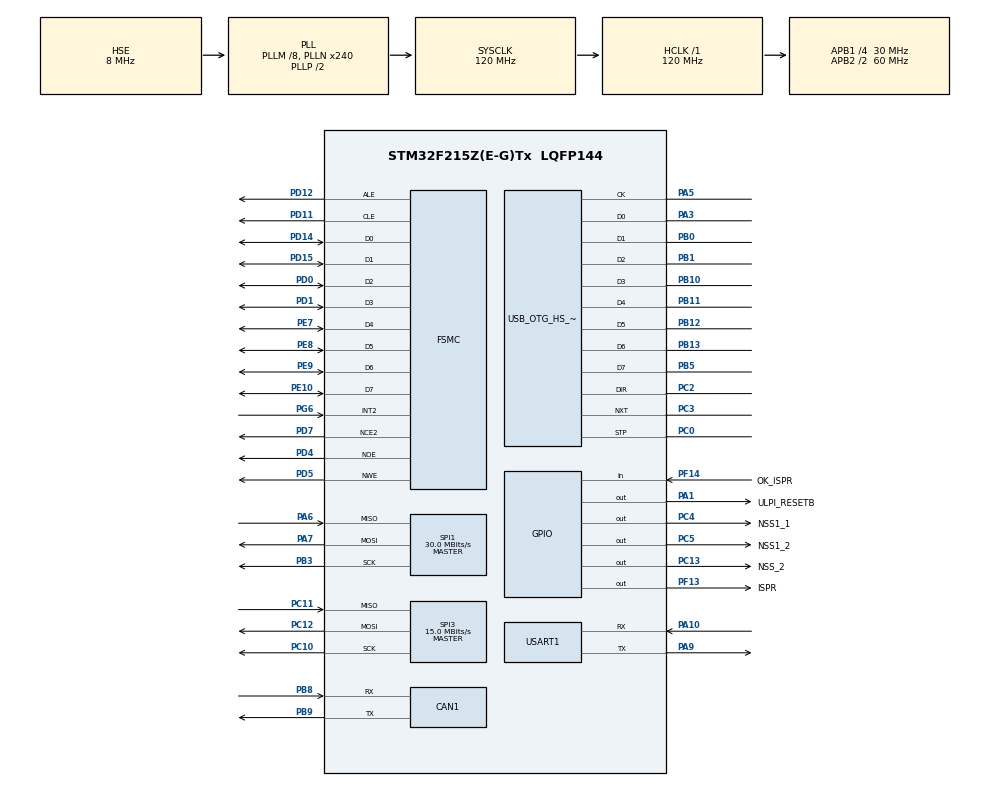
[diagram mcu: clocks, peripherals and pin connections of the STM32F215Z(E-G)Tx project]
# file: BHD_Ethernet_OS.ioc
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CAN1.BS1=CAN_BS1_1TQ
CAN1.BS2=CAN_BS2_1TQ
CAN1.CalculateTimeQuantum=533.3333333333334
Dma.Request0=USART1_RX
Dma.Request1=USART1_TX
Dma.Request2=SPI1_RX
Dma.Request3=SPI1_TX
Dma.Request4=SPI3_RX
Dma.Request5=SPI3_TX
Dma.SPI1_RX.2.Direction=DMA_PERIPH_TO_MEMORY
Dma.SPI1_RX.2.FIFOMode=DMA_FIFOMODE_DISABLE
Dma.SPI1_RX.2.Instance=DMA2_Stream0
Dma.SPI1_RX.2.MemDataAlignment=DMA_MDATAALIGN_BYTE
Dma.SPI1_RX.2.MemInc=DMA_MINC_ENABLE
Dma.SPI1_RX.2.Mode=DMA_NORMAL
Dma.SPI1_RX.2.PeriphDataAlignment=DMA_PDATAALIGN_BYTE
Dma.SPI1_RX.2.PeriphInc=DMA_PINC_DISABLE
Dma.SPI1_RX.2.Priority=DMA_PRIORITY_LOW
Dma.SPI1_TX.3.Direction=DMA_MEMORY_TO_PERIPH
Dma.SPI1_TX.3.FIFOMode=DMA_FIFOMODE_DISABLE
Dma.SPI1_TX.3.Instance=DMA2_Stream3
Dma.SPI1_TX.3.MemDataAlignment=DMA_MDATAALIGN_BYTE
Dma.SPI1_TX.3.MemInc=DMA_MINC_ENABLE
Dma.SPI1_TX.3.Mode=DMA_NORMAL
Dma.SPI1_TX.3.PeriphDataAlignment=DMA_PDATAALIGN_BYTE
Dma.SPI1_TX.3.PeriphInc=DMA_PINC_DISABLE
Dma.SPI1_TX.3.Priority=DMA_PRIORITY_LOW
Dma.SPI3_RX.4.Direction=DMA_PERIPH_TO_MEMORY
Dma.SPI3_RX.4.FIFOMode=DMA_FIFOMODE_DISABLE
Dma.SPI3_RX.4.Instance=DMA1_Stream0
Dma.SPI3_RX.4.MemDataAlignment=DMA_MDATAALIGN_BYTE
Dma.SPI3_RX.4.MemInc=DMA_MINC_ENABLE
Dma.SPI3_RX.4.Mode=DMA_NORMAL
Dma.SPI3_RX.4.PeriphDataAlignment=DMA_PDATAALIGN_BYTE
Dma.SPI3_RX.4.PeriphInc=DMA_PINC_DISABLE
Dma.SPI3_RX.4.Priority=DMA_PRIORITY_LOW
Dma.SPI3_TX.5.Direction=DMA_MEMORY_TO_PERIPH
Dma.SPI3_TX.5.FIFOMode=DMA_FIFOMODE_DISABLE
Dma.SPI3_TX.5.Instance=DMA1_Stream5
Dma.SPI3_TX.5.MemDataAlignment=DMA_MDATAALIGN_BYTE
Dma.SPI3_TX.5.MemInc=DMA_MINC_ENABLE
Dma.SPI3_TX.5.Mode=DMA_NORMAL
Dma.SPI3_TX.5.PeriphDataAlignment=DMA_PDATAALIGN_BYTE
Dma.SPI3_TX.5.PeriphInc=DMA_PINC_DISABLE
Dma.SPI3_TX.5.Priority=DMA_PRIORITY_LOW
Dma.USART1_RX.0.Direction=DMA_PERIPH_TO_MEMORY
Dma.USART1_RX.0.FIFOMode=DMA_FIFOMODE_DISABLE
Dma.USART1_RX.0.Instance=DMA2_Stream2
Dma.USART1_RX.0.MemDataAlignment=DMA_MDATAALIGN_BYTE
Dma.USART1_RX.0.MemInc=DMA_MINC_ENABLE
Dma.USART1_RX.0.Mode=DMA_NORMAL
Dma.USART1_RX.0.PeriphDataAlignment=DMA_PDATAALIGN_BYTE
Dma.USART1_RX.0.PeriphInc=DMA_PINC_DISABLE
Dma.USART1_RX.0.Priority=DMA_PRIORITY_LOW
Dma.USART1_TX.1.Direction=DMA_MEMORY_TO_PERIPH
Dma.USART1_TX.1.FIFOMode=DMA_FIFOMODE_DISABLE
Dma.USART1_TX.1.Instance=DMA2_Stream7
Dma.USART1_TX.1.MemDataAlignment=DMA_MDATAALIGN_BYTE
Dma.USART1_TX.1.MemInc=DMA_MINC_ENABLE
Dma.USART1_TX.1.Mode=DMA_NORMAL
Dma.USART1_TX.1.PeriphDataAlignment=DMA_PDATAALIGN_BYTE
Dma.USART1_TX.1.PeriphInc=DMA_PINC_DISABLE
Dma.USART1_TX.1.Priority=DMA_PRIORITY_LOW
FREERTOS.Tasks01=defaultTask,24,128,StartDefaultTask,Default,NULL,Dynamic,NULL,NULL
FREERTOS.configCHECK_FOR_STACK_OVERFLOW=2
FREERTOS.configUSE_MALLOC_FAILED_HOOK=1
FREERTOS.configUSE_TICK_HOOK=1
Mcu.Family=STM32F2
Mcu.Name=STM32F215Z(E-G)Tx
Mcu.Package=LQFP144
NVIC.DMA1_Stream0_IRQn=true\:5\:0\:false\:false\:true\:true\:false\:true
NVIC.DMA1_Stream5_IRQn=true\:5\:0\:false\:false\:true\:true\:false\:true
NVIC.DMA2_Stream0_IRQn=true\:5\:0\:false\:false\:true\:true\:false\:true
NVIC.DMA2_Stream2_IRQn=true\:5\:0\:false\:false\:true\:true\:false\:true
NVIC.DMA2_Stream3_IRQn=true\:5\:0\:false\:false\:true\:true\:false\:true
NVIC.DMA2_Stream7_IRQn=true\:5\:0\:false\:false\:true\:true\:false\:true
NVIC.OTG_HS_IRQn=true\:5\:0\:false\:false\:true\:true\:false\:true
NVIC.PriorityGroup=NVIC_PRIORITYGROUP_4
NVIC.TIM1_UP_TIM10_IRQn=true\:0\:0\:false\:false\:true\:false\:false\:true
NVIC.TimeBase=TIM1_UP_TIM10_IRQn
NVIC.TimeBaseIP=TIM10
PA1.GPIO_Label=ULPI_RESETB
PA1.Signal=GPIO_Output
PA10.Mode=Asynchronous
PA10.Signal=USART1_RX
PA13.Mode=Serial_Wire
PA13.Signal=SYS_JTMS-SWDIO
PA14.Mode=Serial_Wire
PA14.Signal=SYS_JTCK-SWCLK
PA3.Mode=Device_HS
PA3.Signal=USB_OTG_HS_ULPI_D0
PA5.Mode=Device_HS
PA5.Signal=USB_OTG_HS_ULPI_CK
PA6.Mode=Full_Duplex_Master
PA6.Signal=SPI1_MISO
PA7.Mode=Full_Duplex_Master
PA7.Signal=SPI1_MOSI
PA9.Mode=Asynchronous
PA9.Signal=USART1_TX
PB0.Mode=Device_HS
PB0.Signal=USB_OTG_HS_ULPI_D1
PB1.Mode=Device_HS
PB1.Signal=USB_OTG_HS_ULPI_D2
PB10.Mode=Device_HS
PB10.Signal=USB_OTG_HS_ULPI_D3
PB11.Mode=Device_HS
PB11.Signal=USB_OTG_HS_ULPI_D4
PB12.Mode=Device_HS
PB12.Signal=USB_OTG_HS_ULPI_D5
PB13.Mode=Device_HS
PB13.Signal=USB_OTG_HS_ULPI_D6
PB3.Mode=Full_Duplex_Master
PB3.Signal=SPI1_SCK
PB5.Mode=Device_HS
PB5.Signal=USB_OTG_HS_ULPI_D7
PB8.Mode=Master
PB8.Signal=CAN1_RX
PB9.Mode=Master
PB9.Signal=CAN1_TX
PC0.Mode=Device_HS
PC0.Signal=USB_OTG_HS_ULPI_STP
PC10.Mode=Full_Duplex_Master
PC10.Signal=SPI3_SCK
PC11.Mode=Full_Duplex_Master
PC11.Signal=SPI3_MISO
PC12.Mode=Full_Duplex_Master
PC12.Signal=SPI3_MOSI
PC13.GPIO_Label=NSS_2
PC13.Signal=GPIO_Output
PC2.Mode=Device_HS
PC2.Signal=USB_OTG_HS_ULPI_DIR
PC3.Mode=Device_HS
PC3.Signal=USB_OTG_HS_ULPI_NXT
PC4.GPIO_Label=NSS1_1
PC4.Signal=GPIO_Output
PC5.GPIO_Label=NSS1_2
PC5.Signal=GPIO_Output
PD0.Signal=FSMC_D2_DA2
PD1.Signal=FSMC_D3_DA3
PD11.Signal=FSMC_A16_CLE
PD12.Signal=FSMC_A17_ALE
PD14.Signal=FSMC_D0_DA0
PD15.Signal=FSMC_D1_DA1
PD4.Signal=FSMC_NOE
PD5.Signal=FSMC_NWE
PD7.Mode=NandChipSelect2_1
PD7.Signal=FSMC_NCE2
PE10.Signal=FSMC_D7_DA7
PE7.Signal=FSMC_D4_DA4
PE8.Signal=FSMC_D5_DA5
PE9.Signal=FSMC_D6_DA6
PF13.GPIO_Label=ISPR
PF13.Signal=GPIO_Output
PF14.GPIO_Label=OK_ISPR
PF14.Signal=GPIO_Input
PG6.Signal=FSMC_INT2
PH0-OSC_IN.Mode=HSE-External-Oscillator
PH0-OSC_IN.Signal=RCC_OSC_IN
PH1-OSC_OUT.Mode=HSE-External-Oscillator
PH1-OSC_OUT.Signal=RCC_OSC_OUT
ProjectManager.HeapSize=0x200
ProjectManager.StackSize=0x400
ProjectManager.TargetToolchain=MDK-ARM V5.27
RCC.48MHZClocksFreq_Value=60000000
RCC.AHBFreq_Value=120000000
RCC.APB1CLKDivider=RCC_HCLK_DIV4
RCC.APB1Freq_Value=30000000
RCC.APB1TimFreq_Value=60000000
RCC.APB2CLKDivider=RCC_HCLK_DIV2
RCC.APB2Freq_Value=60000000
RCC.APB2TimFreq_Value=120000000
RCC.CortexFreq_Value=120000000
RCC.EnbaleCSS=true
RCC.HCLKFreq_Value=120000000
RCC.HSE_VALUE=8000000
RCC.HSI_VALUE=16000000
RCC.LSE_VALUE=32768
RCC.PLLM=8
RCC.PLLN=240
RCC.PLLSourceVirtual=RCC_PLLSOURCE_HSE
RCC.SYSCLKFreq_VALUE=120000000
RCC.SYSCLKSource=RCC_SYSCLKSOURCE_PLLCLK
RCC.VCOOutputFreq_Value=240000000
SH.FSMC_A16_CLE.0=FSMC_CLE,8b-dmux1
SH.FSMC_A17_ALE.0=FSMC_ALE,8b-dmux1
SH.FSMC_D0_DA0.0=FSMC_D0,8b-dmux1
SH.FSMC_D1_DA1.0=FSMC_D1,8b-dmux1
SH.FSMC_D2_DA2.0=FSMC_D2,8b-dmux1
SH.FSMC_D3_DA3.0=FSMC_D3,8b-dmux1
SH.FSMC_D4_DA4.0=FSMC_D4,8b-dmux1
SH.FSMC_D5_DA5.0=FSMC_D5,8b-dmux1
SH.FSMC_D6_DA6.0=FSMC_D6,8b-dmux1
SH.FSMC_D7_DA7.0=FSMC_D7,8b-dmux1
SH.FSMC_INT2.0=FSMC_INT2,Interrupt21
SH.FSMC_NOE.0=FSMC_NOE,8b-dmux1
SH.FSMC_NWE.0=FSMC_NWE,8b-dmux1
SPI1.BaudRatePrescaler=SPI_BAUDRATEPRESCALER_2
SPI1.CalculateBaudRate=30.0 MBits/s
SPI1.Direction=SPI_DIRECTION_2LINES
SPI1.Mode=SPI_MODE_MASTER
SPI1.VirtualType=VM_MASTER
SPI3.BaudRatePrescaler=SPI_BAUDRATEPRESCALER_2
SPI3.CalculateBaudRate=15.0 MBits/s
SPI3.Direction=SPI_DIRECTION_2LINES
SPI3.Mode=SPI_MODE_MASTER
SPI3.VirtualType=VM_MASTER
USART1.VirtualMode=VM_ASYNC
USB_DEVICE.CLASS_NAME_HS=CDC
USB_DEVICE.VirtualMode-CDC_HS=Cdc
USB_DEVICE.VirtualModeHS=Cdc_HS
USB_OTG_HS.VirtualMode-Device_HS=Device_HS
VP_FREERTOS_VS_CMSIS_V2.Mode=CMSIS_V2
VP_SYS_VS_tim10.Mode=TIM10
VP_USB_DEVICE_VS_USB_DEVICE_CDC_HS.Mode=CDC_HS
board=custom

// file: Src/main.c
/* USER CODE BEGIN Header */
/**
  ******************************************************************************
  * @file           : main.c
  * @brief          : Main program body
  ******************************************************************************
  * @attention
  *
  * <h2><center>&copy; Copyright (c) 2019 STMicroelectronics.
  * All rights reserved.</center></h2>
  *
  * This software component is licensed by ST under Ultimate Liberty license
  * SLA0044, the "License"; You may not use this file except in compliance with
  * the License. You may obtain a copy of the License at:
  *                             www.st.com/SLA0044
  *
  ******************************************************************************
  */
/* USER CODE END Header */

#include "main.h"
#include "cmsis_os.h"
#include "can.h"
#include "dma.h"
#include "spi.h"
#include "usart.h"
#include "usb_device.h"
#include "gpio.h"
#include "fsmc.h"

void SystemClock_Config(void);
void MX_FREERTOS_Init(void);

int main(void)
{

  /* MCU Configuration--------------------------------------------------------*/

  /* Reset of all peripherals, Initializes the Flash interface and the Systick. */
  HAL_Init();

  /* Configure the system clock */
  SystemClock_Config();

  /* Initialize all configured peripherals */
  MX_GPIO_Init();
  MX_DMA_Init();
  MX_CAN1_Init();
  MX_FSMC_Init();
  MX_SPI1_Init();
  MX_SPI3_Init();
  MX_USART1_UART_Init();

  /* Call init function for freertos objects (in freertos.c) */
  MX_FREERTOS_Init();

  /* Start scheduler */
  osKernelStart();

  /* We should never get here as control is now taken by the scheduler */

  /* Infinite loop */
  while (1)
  {

  }
}

void SystemClock_Config(void)
{
  RCC_OscInitTypeDef RCC_OscInitStruct = {0};
  RCC_ClkInitTypeDef RCC_ClkInitStruct = {0};

  /** Initializes the CPU, AHB and APB busses clocks
  */
  RCC_OscInitStruct.OscillatorType = RCC_OSCILLATORTYPE_HSE;
  RCC_OscInitStruct.HSEState = RCC_HSE_ON;
  RCC_OscInitStruct.PLL.PLLState = RCC_PLL_ON;
  RCC_OscInitStruct.PLL.PLLSource = RCC_PLLSOURCE_HSE;
  RCC_OscInitStruct.PLL.PLLM = 8;
  RCC_OscInitStruct.PLL.PLLN = 240;
  RCC_OscInitStruct.PLL.PLLP = RCC_PLLP_DIV2;
  RCC_OscInitStruct.PLL.PLLQ = 4;
  if (HAL_RCC_OscConfig(&RCC_OscInitStruct) != HAL_OK)
  {
    Error_Handler();
  }
  /** Initializes the CPU, AHB and APB busses clocks
  */
  RCC_ClkInitStruct.ClockType = RCC_CLOCKTYPE_HCLK|RCC_CLOCKTYPE_SYSCLK
                              |RCC_CLOCKTYPE_PCLK1|RCC_CLOCKTYPE_PCLK2;
  RCC_ClkInitStruct.SYSCLKSource = RCC_SYSCLKSOURCE_PLLCLK;
  RCC_ClkInitStruct.AHBCLKDivider = RCC_SYSCLK_DIV1;
  RCC_ClkInitStruct.APB1CLKDivider = RCC_HCLK_DIV4;
  RCC_ClkInitStruct.APB2CLKDivider = RCC_HCLK_DIV2;

  if (HAL_RCC_ClockConfig(&RCC_ClkInitStruct, FLASH_LATENCY_3) != HAL_OK)
  {
    Error_Handler();
  }
  /** Enables the Clock Security System
  */
  HAL_RCC_EnableCSS();
}

void HAL_TIM_PeriodElapsedCallback(TIM_HandleTypeDef *htim)
{
  if (htim->Instance == TIM10) {
    HAL_IncTick();
  }
}

void Error_Handler(void)
{
}

/************************ (C) COPYRIGHT STMicroelectronics *****END OF FILE****/

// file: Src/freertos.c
/* USER CODE BEGIN Header */
/**
  ******************************************************************************
  * File Name          : freertos.c
  * Description        : Code for freertos applications
  ******************************************************************************
  * @attention
  *
  * <h2><center>&copy; Copyright (c) 2019 STMicroelectronics.
  * All rights reserved.</center></h2>
  *
  * This software component is licensed by ST under Ultimate Liberty license
  * SLA0044, the "License"; You may not use this file except in compliance with
  * the License. You may obtain a copy of the License at:
  *                             www.st.com/SLA0044
  *
  ******************************************************************************
  */
/* USER CODE END Header */

#include "FreeRTOS.h"
#include "task.h"
#include "main.h"
#include "cmsis_os.h"

osThreadId_t defaultTaskHandle;

void StartDefaultTask(void *argument);

extern void MX_USB_DEVICE_Init(void);
void MX_FREERTOS_Init(void); /* (MISRA C 2004 rule 8.1) */

/* Hook prototypes */
void vApplicationTickHook(void);
void vApplicationStackOverflowHook(xTaskHandle xTask, signed char *pcTaskName);
void vApplicationMallocFailedHook(void);

/* USER CODE BEGIN 3 */
void vApplicationTickHook(void)
{
  /* This function will be called by each tick interrupt if
   configUSE_TICK_HOOK is set to 1 in FreeRTOSConfig.h. User code can be
   added here, but the tick hook is called from an interrupt context, so
   code must not attempt to block, and only the interrupt safe FreeRTOS API
   functions can be used (those that end in FromISR()). */
}
/* USER CODE END 3 */

/* USER CODE BEGIN 4 */
void vApplicationStackOverflowHook(xTaskHandle xTask, signed char *pcTaskName)
{
  /* Run time stack overflow checking is performed if
   configCHECK_FOR_STACK_OVERFLOW is defined to 1 or 2. This hook function is
   called if a stack overflow is detected. */
}
/* USER CODE END 4 */

/* USER CODE BEGIN 5 */
void vApplicationMallocFailedHook(void)
{
  /* vApplicationMallocFailedHook() will only be called if
   configUSE_MALLOC_FAILED_HOOK is set to 1 in FreeRTOSConfig.h. It is a hook
   function that will get called if a call to pvPortMalloc() fails.
   pvPortMalloc() is called internally by the kernel whenever a task, queue,
   timer or semaphore is created. It is also called by various parts of the
   demo application. If heap_1.c or heap_2.c are used, then the size of the
   heap available to pvPortMalloc() is defined by configTOTAL_HEAP_SIZE in
   FreeRTOSConfig.h, and the xPortGetFreeHeapSize() API function can be used
   to query the size of free heap space that remains (although it does not
   provide information on how the remaining heap might be fragmented). */
}
/* USER CODE END 5 */

void MX_FREERTOS_Init(void)
{
  osKernelInitialize();

  /* Create the thread(s) */
  /* definition and creation of defaultTask */
  const osThreadAttr_t defaultTask_attributes = {
      .name = "defaultTask",
      .priority = (osPriority_t)osPriorityNormal,
      .stack_size = 128};
  defaultTaskHandle = osThreadNew(StartDefaultTask, NULL, &defaultTask_attributes);

}

void StartDefaultTask(void *argument)
{
  /* init code for USB_DEVICE */
  MX_USB_DEVICE_Init();
  for (;;)
  {
    osDelay(1);
  }
}

/************************ (C) COPYRIGHT STMicroelectronics *****END OF FILE****/
